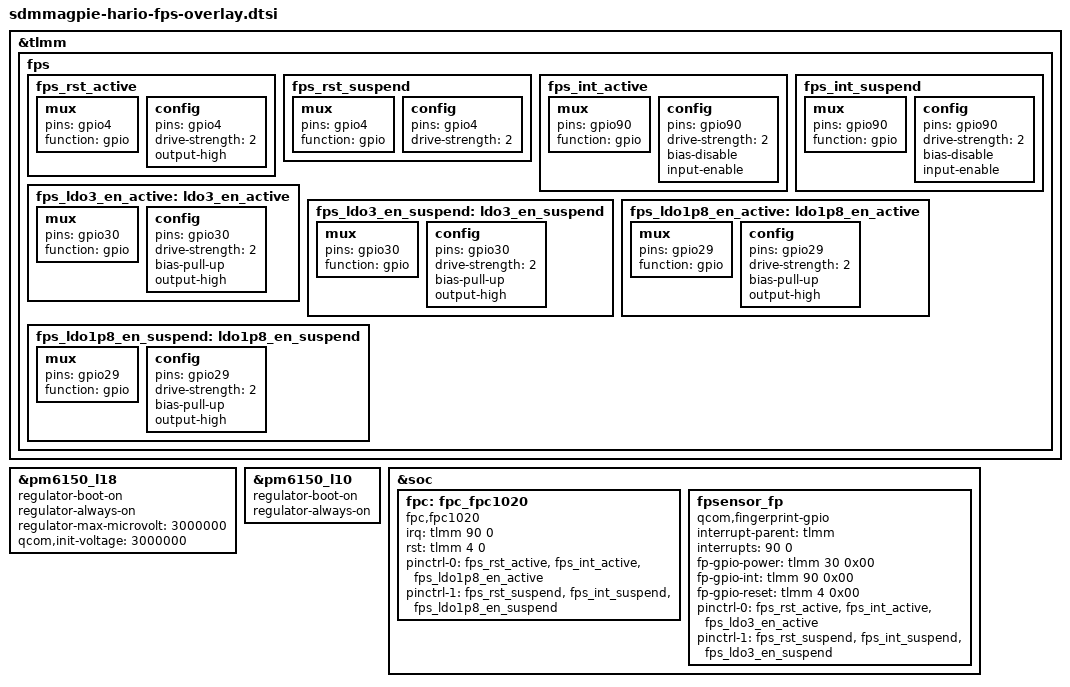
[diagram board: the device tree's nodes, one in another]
&tlmm {
	fps {
		fps_rst_active: fps_rst_active {
			/* active state */
			mux {
				pins = "gpio4";
				function = "gpio";
			};

			config {
				pins = "gpio4";
				drive-strength = <2>; /* 2 MA */
				output-high;
			};
		};

		fps_rst_suspend: fps_rst_suspend {
			/* sleep state */
			mux {
				pins = "gpio4";
				function = "gpio";
			};

			config {
				pins = "gpio4";
				drive-strength = <2>; /* 2 MA */
			};
		};

		fps_int_active: fps_int_active {
			/* active state */
			mux {
				pins = "gpio90";
				function = "gpio";
			};

			config {
				pins = "gpio90";
				drive-strength = <2>; /* 2 MA */
				bias-disable;
				input-enable;
			};
		};

		fps_int_suspend: fps_int_suspend {
			/* sleep state */
			mux {
				pins = "gpio90";
				function = "gpio";
			};

			config {
				pins = "gpio90";
				drive-strength = <2>; /* 2 MA */
				bias-disable;
				input-enable;
			};
		};

		fps_ldo3_en_active: ldo3_en_active {
			/* active state */
			mux {
				pins = "gpio30";
				function = "gpio";
			};

			config {
				pins = "gpio30";
				drive-strength = <2>; /* 2 MA */
				bias-pull-up;
				output-high;
			};
		};

		fps_ldo3_en_suspend: ldo3_en_suspend {
			/* suspend state */
			mux {
				pins = "gpio30";
				function = "gpio";
			};

			config {
				pins = "gpio30";
				drive-strength = <2>; /* 2 MA */
				bias-pull-up;
				output-high;
			};
		};

		fps_ldo1p8_en_active: ldo1p8_en_active {
			/* active state */
			mux {
				pins = "gpio29";
				function = "gpio";
			};

			config {
				pins = "gpio29";
				drive-strength = <2>; /* 2 MA */
				bias-pull-up;
				output-high;
			};
		};

		fps_ldo1p8_en_suspend: ldo1p8_en_suspend {
			/* suspend state */
			mux {
				pins = "gpio29";
				function = "gpio";
			};

			config {
				pins = "gpio29";
				drive-strength = <2>; /* 2 MA */
				bias-pull-up;
				output-high;
			};
		};

	};
};

&pm6150_l18 {
	regulator-boot-on;
	regulator-always-on;
	regulator-max-microvolt = <3000000>;
	qcom,init-voltage = <3000000>;
	status = "ok";
};
/*7150 already sets 1.8v always on in rpm side */
&pm6150_l10 {
	regulator-boot-on;
	regulator-always-on;
	status = "ok";
};
&soc {

	fpc: fpc_fpc1020 {
		compatible = "fpc,fpc1020";
		status = "ok";
		irq = <&tlmm 90 0>;
		rst = <&tlmm 4 0>;
		pinctrl-names = "default", "suspend";
		pinctrl-0 = <&fps_rst_active &fps_int_active &fps_ldo1p8_en_active>;
		pinctrl-1 = <&fps_rst_suspend &fps_int_suspend &fps_ldo1p8_en_suspend>;
	};

	fpsensor_fp {
		status = "ok";
		compatible = "qcom,fingerprint-gpio";
		interrupt-parent = <&tlmm>;
		interrupts = <90 0>;
		fp-gpio-power = <&tlmm 30 0x00>;
		fp-gpio-int   = <&tlmm 90 0x00>;
		fp-gpio-reset = <&tlmm 4 0x00>;
		pinctrl-names = "default", "suspend";
		pinctrl-0 = <&fps_rst_active &fps_int_active &fps_ldo3_en_active>;
		pinctrl-1 = <&fps_rst_suspend &fps_int_suspend &fps_ldo3_en_suspend>;
	};

};
